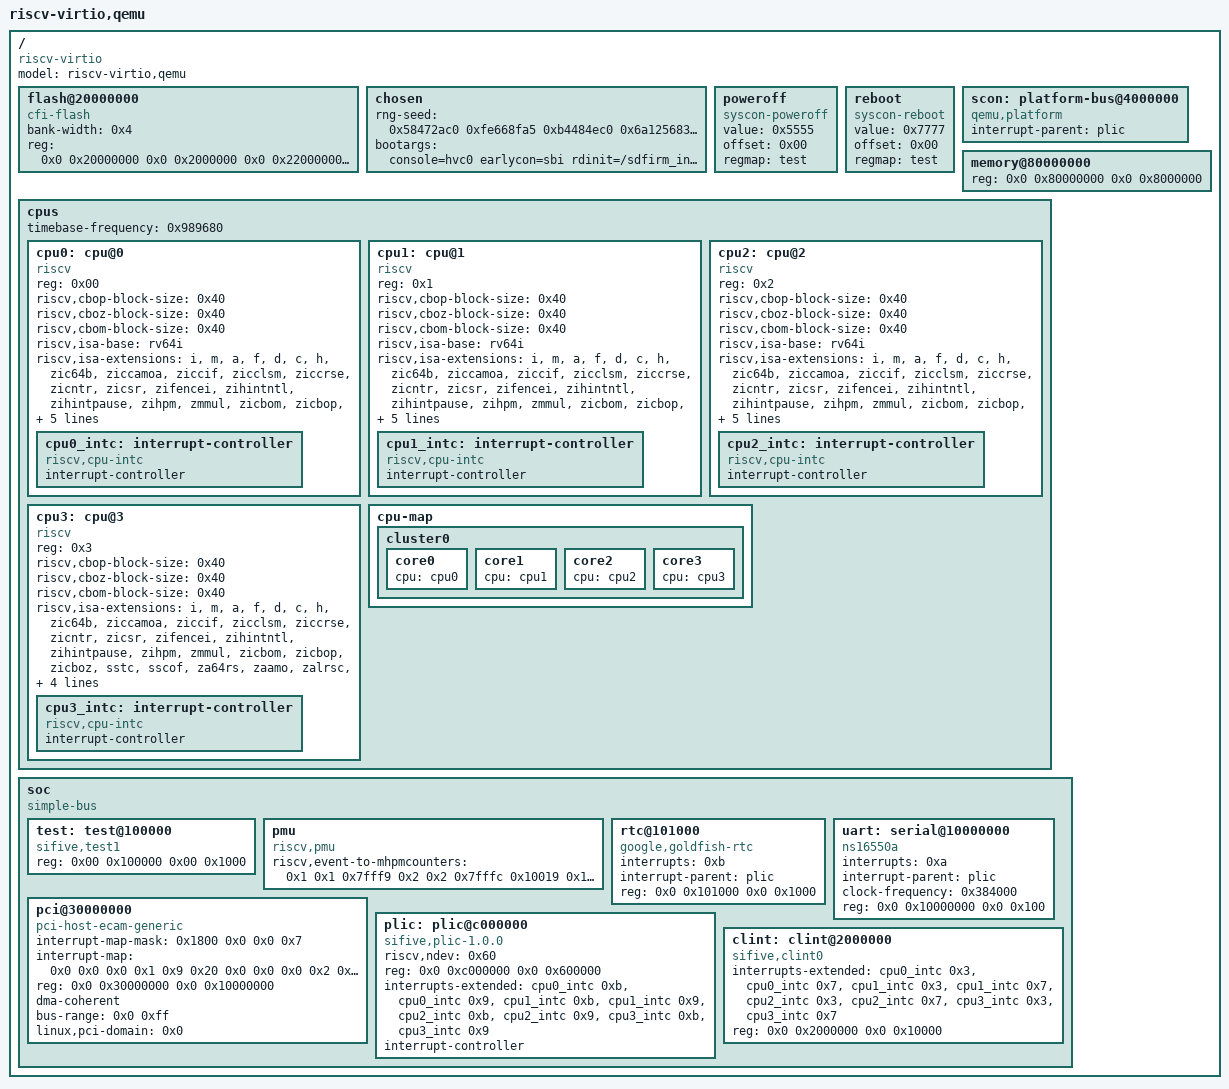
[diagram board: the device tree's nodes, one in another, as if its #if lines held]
#include <target/arch.h>

/dts-v1/;

/ {
	#address-cells = <0x2>;
	#size-cells = <0x2>;
	compatible = "riscv-virtio";
	model = "riscv-virtio,qemu";

	flash@20000000 {
		bank-width = <0x4>;
		reg = <0x0 0x20000000 0x0 0x2000000 0x0 0x22000000 0x0 0x2000000>;
		compatible = "cfi-flash";
	};

	chosen {
		rng-seed = <0x58472ac0 0xfe668fa5 0xb4484ec0 0x6a125683 0x289b8433 0x1577b616 0xd6105098 0xe55ad8ad>;
#ifdef CONFIG_VIRT_UART_CON_HVC
		bootargs = "console=hvc0 earlycon=sbi rdinit=/sdfirm_init";
#else
		stdout-path = &uart;
		bootargs = "console=ttyS0 earlycon rdinit=/sdfirm_init";
#endif
	};

	poweroff {
		value = <0x5555>;
		offset = <0x00>;
		regmap = <&test>;
		compatible = "syscon-poweroff";
	};

	reboot {
		value = <0x7777>;
		offset = <0x00>;
		regmap = <&test>;
		compatible = "syscon-reboot";
	};

	scon: platform-bus@4000000 {
		interrupt-parent = <&plic>;
		ranges = <0x00 0x00 0x4000000 0x2000000>;
		#address-cells = <0x01>;
		#size-cells = <0x01>;
		compatible = "qemu,platform", "simple-bus";
	};

	memory@80000000 {
		device_type = "memory";
		reg = <0x0 0x80000000 0x0 0x8000000>;
	};

	cpus {
		#address-cells = <0x1>;
		#size-cells = <0x0>;
		timebase-frequency = <0x989680>;

		cpu0: cpu@0 {
			device_type = "cpu";
			reg = <0x00>;
			status = "okay";
			compatible = "riscv";
			riscv,cbop-block-size = <0x40>;
			riscv,cboz-block-size = <0x40>;
			riscv,cbom-block-size = <0x40>;
			riscv,isa-base = "rv64i";
			riscv,isa-extensions = "i", "m", "a", "f", "d"
#ifdef CONFIG_RISCV_C
					     , "c"
#endif
					     , "h"
					     , "zic64b"
					     , "ziccamoa", "ziccif", "zicclsm", "ziccrse"
					     , "zicntr"
					     , "zicsr", "zifencei"
					     , "zihintntl", "zihintpause"
					     , "zihpm"
					     , "zmmul"
#ifdef CONFIG_RISCV_ZICBOM
					     , "zicbom"
#endif
#ifdef CONFIG_RISCV_ZICBOP
					     , "zicbop"
#endif
#ifdef CONFIG_RISCV_ZICBOZ
					     , "zicboz"
#endif
#ifdef CONFIG_RISCV_SSTC
					     , "sstc"
#endif
					     , "sscof"
					     , "za64rs"
					     , "zaamo"
					     , "zalrsc"
					     , "zawrs"
					     , "zfa", "zca", "zcd", "zba" , "zbb", "zbc", "zbs"
					     , "ssccptr"
					     , "sscounterenw"
					     , "sstvala"
					     , "sstvecd"
					     , "svadu"
					     ;
			mmu-type = "riscv,sv57";

			cpu0_intc: interrupt-controller {
				#interrupt-cells = <0x01>;
				interrupt-controller;
				compatible = "riscv,cpu-intc";
			};
		};
#ifdef CONFIG_SMP
#if CONFIG_VIRT_SMP_CPUS > 1
		cpu1: cpu@1 {
			device_type = "cpu";
			reg = <0x1>;
			status = "okay";
			compatible = "riscv";
			riscv,cbop-block-size = <0x40>;
			riscv,cboz-block-size = <0x40>;
			riscv,cbom-block-size = <0x40>;
			riscv,isa-base = "rv64i";
			riscv,isa-extensions = "i", "m", "a", "f", "d"
#ifdef CONFIG_RISCV_C
					     , "c"
#endif
					     , "h"
					     , "zic64b"
					     , "ziccamoa", "ziccif", "zicclsm", "ziccrse"
					     , "zicntr"
					     , "zicsr", "zifencei"
					     , "zihintntl", "zihintpause"
					     , "zihpm"
					     , "zmmul"
#ifdef CONFIG_RISCV_ZICBOM
					     , "zicbom"
#endif
#ifdef CONFIG_RISCV_ZICBOP
					     , "zicbop"
#endif
#ifdef CONFIG_RISCV_ZICBOZ
					     , "zicboz"
#endif
#ifdef CONFIG_RISCV_SSTC
					     , "sstc"
#endif
					     , "sscof"
					     , "za64rs"
					     , "zaamo"
					     , "zalrsc"
					     , "zawrs"
					     , "zfa", "zca", "zcd", "zba" , "zbb", "zbc", "zbs"
					     , "ssccptr"
					     , "sscounterenw"
					     , "sstvala"
					     , "sstvecd"
					     , "svadu"
					     ;
			mmu-type = "riscv,sv57";

			cpu1_intc: interrupt-controller {
				#interrupt-cells = <0x1>;
				interrupt-controller;
				compatible = "riscv,cpu-intc";
			};
		};
#endif
#if CONFIG_VIRT_SMP_CPUS > 2
		cpu2: cpu@2 {
			device_type = "cpu";
			reg = <0x2>;
			status = "okay";
			compatible = "riscv";
			riscv,cbop-block-size = <0x40>;
			riscv,cboz-block-size = <0x40>;
			riscv,cbom-block-size = <0x40>;
			riscv,isa-base = "rv64i";
			riscv,isa-extensions = "i", "m", "a", "f", "d"
#ifdef CONFIG_RISCV_C
					     , "c"
#endif
					     , "h"
					     , "zic64b"
					     , "ziccamoa", "ziccif", "zicclsm", "ziccrse"
					     , "zicntr"
					     , "zicsr", "zifencei"
					     , "zihintntl", "zihintpause"
					     , "zihpm"
					     , "zmmul"
#ifdef CONFIG_RISCV_ZICBOM
					     , "zicbom"
#endif
#ifdef CONFIG_RISCV_ZICBOP
					     , "zicbop"
#endif
#ifdef CONFIG_RISCV_ZICBOZ
					     , "zicboz"
#endif
#ifdef CONFIG_RISCV_SSTC
					     , "sstc"
#endif
					     , "sscof"
					     , "za64rs"
					     , "zaamo"
					     , "zalrsc"
					     , "zawrs"
					     , "zfa", "zca", "zcd", "zba" , "zbb", "zbc", "zbs"
					     , "ssccptr"
					     , "sscounterenw"
					     , "sstvala"
					     , "sstvecd"
					     , "svadu"
					     ;
			mmu-type = "riscv,sv57";

			cpu2_intc: interrupt-controller {
				#interrupt-cells = <0x1>;
				interrupt-controller;
				compatible = "riscv,cpu-intc";
			};
		};
#endif
#if CONFIG_VIRT_SMP_CPUS > 3
		cpu3: cpu@3 {
			device_type = "cpu";
			reg = <0x3>;
			status = "okay";
			compatible = "riscv";
			riscv,cbop-block-size = <0x40>;
			riscv,cboz-block-size = <0x40>;
			riscv,cbom-block-size = <0x40>;
			riscv,isa-extensions = "i", "m", "a", "f", "d"
#ifdef CONFIG_RISCV_C
					     , "c"
#endif
					     , "h"
					     , "zic64b"
					     , "ziccamoa", "ziccif", "zicclsm", "ziccrse"
					     , "zicntr"
					     , "zicsr", "zifencei"
					     , "zihintntl", "zihintpause"
					     , "zihpm"
					     , "zmmul"
#ifdef CONFIG_RISCV_ZICBOM
					     , "zicbom"
#endif
#ifdef CONFIG_RISCV_ZICBOP
					     , "zicbop"
#endif
#ifdef CONFIG_RISCV_ZICBOZ
					     , "zicboz"
#endif
#ifdef CONFIG_RISCV_SSTC
					     , "sstc"
#endif
					     , "sscof"
					     , "za64rs"
					     , "zaamo"
					     , "zalrsc"
					     , "zawrs"
					     , "zfa", "zca", "zcd", "zba" , "zbb", "zbc", "zbs"
					     , "ssccptr"
					     , "sscounterenw"
					     , "sstvala"
					     , "sstvecd"
					     , "svadu"
					     ;
			mmu-type = "riscv,sv57";

			cpu3_intc: interrupt-controller {
				#interrupt-cells = <0x1>;
				interrupt-controller;
				compatible = "riscv,cpu-intc";
			};
		};
#endif
#endif

		cpu-map {
			cluster0 {
				core0 {
					cpu = <&cpu0>;
				};
#ifdef CONFIG_SMP
#if CONFIG_VIRT_SMP_CPUS > 1
				core1 {
					cpu = <&cpu1>;
				};
#endif
#if CONFIG_VIRT_SMP_CPUS > 2
				core2 {
					cpu = <&cpu2>;
				};
#endif
#if CONFIG_VIRT_SMP_CPUS > 3
				core3 {
					cpu = <&cpu3>;
				};
#endif
#endif
			};
		};
	};

	soc {
		#address-cells = <0x2>;
		#size-cells = <0x2>;
		compatible = "simple-bus";
		ranges;

		test: test@100000 {
			phandle = <0x04>;
			reg = <0x00 0x100000 0x00 0x1000>;
			compatible = "sifive,test1", "sifive,test0", "syscon";
		};

		pmu {
			riscv,event-to-mhpmcounters = <0x1 0x1 0x7fff9 0x2 0x2 0x7fffc 0x10019 0x10019 0x7fff8 0x1001b 0x1001b 0x7fff8 0x10021 0x10021 0x7fff8 0x0 0x0 0x0 0x0 0x0>;
			compatible = "riscv,pmu";
		};

		rtc@101000 {
			interrupts = <0xb>;
			interrupt-parent = <&plic>;
			reg = <0x0 0x101000 0x0 0x1000>;
			compatible = "google,goldfish-rtc";
		};

		uart: serial@10000000 {
			interrupts = <0xa>;
			interrupt-parent = <&plic>;
			clock-frequency = <0x384000>;
			reg = <0x0 0x10000000 0x0 0x100>;
			compatible = "ns16550a";
		};

		pci@30000000 {
			interrupt-map-mask = <0x1800 0x0 0x0 0x7>;
			interrupt-map = <0x0 0x0 0x0 0x1 0x9 0x20 0x0 0x0 0x0 0x2 0x9 0x21 0x0 0x0 0x0 0x3 0x9 0x22 0x0 0x0 0x0 0x4 0x9 0x23 0x800 0x0 0x0 0x1 0x9 0x21 0x800 0x0 0x0 0x2 0x9 0x22 0x800 0x0 0x0 0x3 0x9 0x23 0x800 0x0 0x0 0x4 0x9 0x20 0x1000 0x0 0x0 0x1 0x9 0x22 0x1000 0x0 0x0 0x2 0x9 0x23 0x1000 0x0 0x0 0x3 0x9 0x20 0x1000 0x0 0x0 0x4 0x9 0x21 0x1800 0x0 0x0 0x1 0x9 0x23 0x1800 0x0 0x0 0x2 0x9 0x20 0x1800 0x0 0x0 0x3 0x9 0x21 0x1800 0x0 0x0 0x4 0x9 0x22>;
			ranges = <0x1000000 0x0 0x0 0x0 0x3000000 0x0 0x10000 0x2000000 0x0 0x40000000 0x0 0x40000000 0x0 0x40000000 0x3000000 0x4 0x0 0x4 0x0 0x4 0x0>;
			reg = <0x0 0x30000000 0x0 0x10000000>;
			dma-coherent;
			bus-range = <0x0 0xff>;
			linux,pci-domain = <0x0>;
			device_type = "pci";
			compatible = "pci-host-ecam-generic";
			#size-cells = <0x2>;
			#interrupt-cells = <0x1>;
			#address-cells = <0x3>;
		};

		plic: plic@c000000 {
			riscv,ndev = <0x60>;
			reg = <0x0 0xc000000 0x0 0x600000>;
			interrupts-extended = <&cpu0_intc 0xb &cpu0_intc 0x9
#ifdef CONFIG_SMP
#if CONFIG_VIRT_SMP_CPUS > 1
					       &cpu1_intc 0xb &cpu1_intc 0x9
#endif
#if CONFIG_VIRT_SMP_CPUS > 2
					       &cpu2_intc 0xb &cpu2_intc 0x9
#endif
#if CONFIG_VIRT_SMP_CPUS > 3
					       &cpu3_intc 0xb &cpu3_intc 0x9
#endif
#endif
					      >;
			interrupt-controller;
			compatible = "sifive,plic-1.0.0", "riscv,plic0";
			#address-cells = <0x0>;
			#interrupt-cells = <0x1>;
		};

		clint: clint@2000000 {
			interrupts-extended = <&cpu0_intc 0x3 &cpu0_intc 0x7
#ifdef CONFIG_SMP
#if CONFIG_VIRT_SMP_CPUS > 1
					       &cpu1_intc 0x3 &cpu1_intc 0x7
#endif
#if CONFIG_VIRT_SMP_CPUS > 2
					       &cpu2_intc 0x3 &cpu2_intc 0x7
#endif
#if CONFIG_VIRT_SMP_CPUS > 3
					       &cpu3_intc 0x3 &cpu3_intc 0x7
#endif
#endif
					      >;
			reg = <0x0 0x2000000 0x0 0x10000>;
			compatible = "sifive,clint0", "riscv,clint0";
		};
	};
};
